# STM32H503 register map
File version: 0.3
CPU: CM33 r0p0, little endian, MPU, FPU, 4 interrupt priority bits
Registers are 32-bit, read-write, reset 0x0 unless marked. A register's access mark holds for its fields unless they carry their own. Offsets are from the block's base; [hi:lo] are bit positions.

## CRC — Cyclic redundancy check calculation unit
Base 0x40023000
0x00 DR reset 0xFFFFFFFF — CRC data register
  [31:0] DR — Data register bits This register is used to write new data to the CRC calculator. It holds the previous CRC calculation result when it is read. If the data size is less than 32 bits, the least significant bits are used to write/read the correct value.
0x04 IDR — CRC independent data register
  [31:0] IDR — General-purpose 32-bit data register bits These bits can be used as a temporary storage location for four bytes. This register is not affected by CRC resets generated by the RESET bit in the CRC_CR register
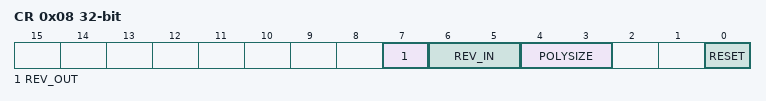
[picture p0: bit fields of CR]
0x08 CR — CRC control register
  [7] REV_OUT — Reverse output data This bit controls the reversal of the bit order of the output data.
  [6:5] REV_IN — Reverse input data These bits control the reversal of the bit order of the input data
  [4:3] POLYSIZE — Polynomial size These bits control the size of the polynomial.
  [0] RESET — RESET bit This bit is set by software to reset the CRC calculation unit and set the data register to the value stored in the CRC_INIT register. This bit can only be set, it is automatically cleared by hardware
0x10 INIT reset 0xFFFFFFFF — CRC initial value
  [31:0] CRC_INIT — Programmable initial CRC value This register is used to write the CRC initial value.
0x14 POL reset 0x4C11DB7 — CRC polynomial
  [31:0] POL — Programmable polynomial This register is used to write the coefficients of the polynomial to be used for CRC calculation. If the polynomial size is less than 32 bits, the least significant bits have to be used to program the correct value.

## ICACHE — Instruction cache
Base 0x40030400
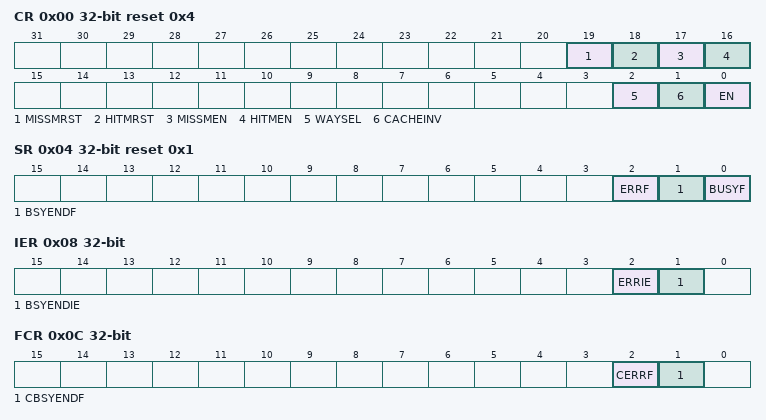
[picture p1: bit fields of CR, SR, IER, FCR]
0x00 CR access per field reset 0x4 — ICACHE control register
  [19] MISSMRST rw — miss monitor reset
  [18] HITMRST rw — hit monitor reset
  [17] MISSMEN rw — miss monitor enable
  [16] HITMEN rw — hit monitor enable
  [2] WAYSEL rw — cache associativity mode selection This bit allows user to choose ICACHE set-associativity. It can be written by software only when cache is disabled (EN = 0).
  [1] CACHEINV wo — cache invalidation Set by software and cleared by hardware when the BUSYF flag is set (during cache maintenance operation). Writing 0 has no effect.
  [0] EN rw — enable
0x04 SR ro reset 0x1 — ICACHE status register
  [2] ERRF — cache error flag
  [1] BSYENDF — busy end flag
  [0] BUSYF — busy flag
0x08 IER — ICACHE interrupt enable register
  [2] ERRIE — interrupt enable on cache error Set by software to enable an interrupt generation in case of cache functional error (cacheable write access)
  [1] BSYENDIE — interrupt enable on busy end Set by software to enable an interrupt generation at the end of a cache invalidate operation.
0x0C FCR wo — ICACHE flag clear register
  [2] CERRF — clear cache error flag Set by software.
  [1] CBSYENDF — clear busy end flag Set by software.
0x10 HMONR ro — ICACHE hit monitor register
  [31:0] HITMON — cache hit monitor counter
0x14 MMONR ro — ICACHE miss monitor register
  [15:0] MISSMON — cache miss monitor counter

## OPAMP1 — Operational amplifiers
Base 0x40003400
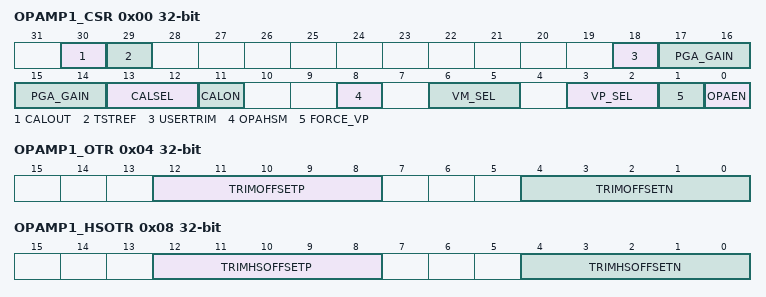
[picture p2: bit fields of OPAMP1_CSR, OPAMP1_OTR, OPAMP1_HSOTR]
0x00 OPAMP1_CSR access per field — OPAMP1 control/status register
  [30] CALOUT ro — Operational amplifier calibration output OPAMP output status flag. During the calibration mode, OPAMP is used as comparator.
  [29] TSTREF rw — OPAMP calibration reference voltage output control (reserved for test)
  [18] USERTRIM rw — User trimming enable This bit allows to switch from ‘factory’ AOP offset trimmed values to ‘user’ AOP offset trimmed values This bit is active for both mode normal and high-power.
  [17:14] PGA_GAIN rw — Operational amplifier Programmable amplifier gain value
  [13:12] CALSEL rw — Calibration selection It is used to select the offset calibration bus used to generate the internal reference voltage when CALON = 1 or FORCE_VP= 1.
  [11] CALON rw — Calibration mode enabled
  [8] OPAHSM rw — Operational amplifier high-speed mode The operational amplifier must be disable to change this configuration.
  [6:5] VM_SEL rw — Inverting input selection
  [3:2] VP_SEL rw — Non inverted input selection
  [1] FORCE_VP rw — Force internal reference on VP (reserved for test)
  [0] OPAEN rw — Operational amplifier Enable Note: If OPAMP1 is unconnected in a specific package, it must remain disabled (keep OPAMP1_CSR register default value).
0x04 OPAMP1_OTR (reset mask 0xFFFF0000) — OPAMP1 trimming register in normal mode
  [12:8] TRIMOFFSETP — Trim for PMOS differential pairs
  [4:0] TRIMOFFSETN — Trim for NMOS differential pairs
0x08 OPAMP1_HSOTR (reset mask 0xFFFF0000) — OPAMP1 trimming register in high-speed mode
  [12:8] TRIMHSOFFSETP — High-speed mode trim for PMOS differential pairs
  [4:0] TRIMHSOFFSETN — High-speed mode trim for NMOS differential pairs
0x0C OPAMP_OR access not given — OPAMP option register
